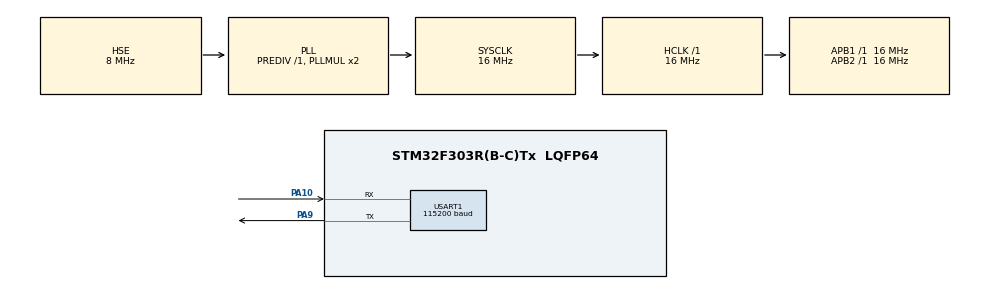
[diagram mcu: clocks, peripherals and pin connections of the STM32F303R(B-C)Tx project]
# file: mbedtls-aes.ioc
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Mcu.Family=STM32F3
Mcu.Name=STM32F303R(B-C)Tx
Mcu.Package=LQFP64
NVIC.PriorityGroup=NVIC_PRIORITYGROUP_4
PA10.Mode=Asynchronous
PA10.Signal=USART1_RX
PA9.Mode=Asynchronous
PA9.Signal=USART1_TX
PF0-OSC_IN.Mode=HSE-External-Oscillator
PF0-OSC_IN.Signal=RCC_OSC_IN
PF1-OSC_OUT.Mode=HSE-External-Oscillator
PF1-OSC_OUT.Signal=RCC_OSC_OUT
ProjectManager.HeapSize=0x200
ProjectManager.StackSize=0x1000
ProjectManager.TargetToolchain=STM32CubeIDE
RCC.AHBFreq_Value=16000000
RCC.APB1Freq_Value=16000000
RCC.APB1TimFreq_Value=16000000
RCC.APB2Freq_Value=16000000
RCC.APB2TimFreq_Value=16000000
RCC.CortexFreq_Value=16000000
RCC.HCLKFreq_Value=16000000
RCC.HSE_VALUE=8000000
RCC.HSI_VALUE=8000000
RCC.LSE_VALUE=32768
RCC.PLLSourceVirtual=RCC_PLLSOURCE_HSE
RCC.SYSCLKFreq_VALUE=16000000
RCC.SYSCLKSourceVirtual=RCC_SYSCLKSOURCE_PLLCLK
RCC.USBFreq_Value=16000000
USART1.BaudRate=115200
USART1.VirtualMode-Asynchronous=VM_ASYNC
board=custom

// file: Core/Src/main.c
/* USER CODE BEGIN Header */
/**
  ******************************************************************************
  * @file           : main.c
  * @brief          : Main program body
  ******************************************************************************
  * @attention
  *
  * Copyright (c) 2024 STMicroelectronics.
  * All rights reserved.
  *
  * This software is licensed under terms that can be found in the LICENSE file
  * in the root directory of this software component.
  * If no LICENSE file comes with this software, it is provided AS-IS.
  *
  ******************************************************************************
  */
/* USER CODE END Header */
#include "main.h"
#include "string.h"

/* USER CODE BEGIN Includes */
#include "mbedtls/config.h"
#include "mbedtls/aes.h"
#define MLEN 32

/* USER CODE END Includes */

UART_HandleTypeDef huart1;

void SystemClock_Config(void);
static void MX_GPIO_Init(void);
static void MX_USART1_UART_Init(void);

int main(void)
{

  /* USER CODE BEGIN 1 */
	mbedtls_aes_context ctx;
	uint8_t key[16] = "AAAAAAAAAACCCCDD";
	const uint8_t iv[16] = {0X00, 0X01, 0X02, 0X03, 0X10, 0X11, 0X12, 0X13, 0X20, 0X21, 0X22, 0X23, 0X30, 0X31, 0X32, 0X33};
	uint8_t tmp_iv[16];
	uint8_t plaintext[MLEN];
	uint8_t ciphertext[MLEN];
	uint8_t pt_output[MLEN];
	int ret = 0;
  /* USER CODE END 1 */

  /* MCU Configuration--------------------------------------------------------*/

  /* Reset of all peripherals, Initializes the Flash interface and the Systick. */
  HAL_Init();

  /* Configure the system clock */
  SystemClock_Config();

  /* Initialize all configured peripherals */
  MX_GPIO_Init();
  MX_USART1_UART_Init();

  /* Infinite loop */
  /* USER CODE BEGIN WHILE */
  while (1)
  {
	  ret = HAL_UART_Receive(&huart1, plaintext, MLEN, HAL_MAX_DELAY);
	  if(ret==HAL_OK)
	  {
	  	  //set the encryption key
	  	  mbedtls_aes_setkey_enc(&ctx, key, 128);
		  __disable_irq();  // disable interrupts
	  	  HAL_GPIO_WritePin(GPIOA, GPIO_PIN_6, 1); // drive the level high before the operation as a trigger signal
	  	  //encrypt
	  	  memcpy(tmp_iv, iv, 16);
	  	  mbedtls_aes_crypt_cbc(&ctx, MBEDTLS_AES_ENCRYPT, MLEN, tmp_iv, plaintext, ciphertext);
	  	  HAL_GPIO_WritePin(GPIOA, GPIO_PIN_6, 0); // drive the level low after the operation
	  	  __enable_irq();  // enable interrupts
	  	  HAL_UART_Transmit(&huart1, ciphertext, MLEN, HAL_MAX_DELAY);

	   	  //set the decryption key
	   	  mbedtls_aes_setkey_dec(&ctx, key, 128);
	  	  __disable_irq();  // disable interrupts
	   	  HAL_GPIO_WritePin(GPIOA, GPIO_PIN_6, 1); // drive the level high before the operation as a trigger signal
 	  	  //decrypt
	   	  memcpy(tmp_iv, iv, 16);
	   	  mbedtls_aes_crypt_cbc(&ctx, MBEDTLS_AES_DECRYPT, MLEN, tmp_iv, ciphertext, pt_output);
	   	  HAL_GPIO_WritePin(GPIOA, GPIO_PIN_6, 0); // drive the level low after the operation
	   	  __enable_irq();  // enable interrupts
	   	  HAL_UART_Transmit(&huart1, pt_output, MLEN, HAL_MAX_DELAY);
	  }
    /* USER CODE END WHILE */

  }
}

void SystemClock_Config(void)
{
  RCC_OscInitTypeDef RCC_OscInitStruct = {0};
  RCC_ClkInitTypeDef RCC_ClkInitStruct = {0};
  RCC_PeriphCLKInitTypeDef PeriphClkInit = {0};

  /** Initializes the RCC Oscillators according to the specified parameters
  * in the RCC_OscInitTypeDef structure.
  */
  RCC_OscInitStruct.OscillatorType = RCC_OSCILLATORTYPE_HSE;
  RCC_OscInitStruct.HSEState = RCC_HSE_ON;
  RCC_OscInitStruct.HSEPredivValue = RCC_HSE_PREDIV_DIV1;
  RCC_OscInitStruct.HSIState = RCC_HSI_ON;
  RCC_OscInitStruct.PLL.PLLState = RCC_PLL_ON;
  RCC_OscInitStruct.PLL.PLLSource = RCC_PLLSOURCE_HSE;
  RCC_OscInitStruct.PLL.PLLMUL = RCC_PLL_MUL2;
  if (HAL_RCC_OscConfig(&RCC_OscInitStruct) != HAL_OK)
  {
    Error_Handler();
  }

  /** Initializes the CPU, AHB and APB buses clocks
  */
  RCC_ClkInitStruct.ClockType = RCC_CLOCKTYPE_HCLK|RCC_CLOCKTYPE_SYSCLK
                              |RCC_CLOCKTYPE_PCLK1|RCC_CLOCKTYPE_PCLK2;
  RCC_ClkInitStruct.SYSCLKSource = RCC_SYSCLKSOURCE_PLLCLK;
  RCC_ClkInitStruct.AHBCLKDivider = RCC_SYSCLK_DIV1;
  RCC_ClkInitStruct.APB1CLKDivider = RCC_HCLK_DIV1;
  RCC_ClkInitStruct.APB2CLKDivider = RCC_HCLK_DIV1;

  if (HAL_RCC_ClockConfig(&RCC_ClkInitStruct, FLASH_LATENCY_0) != HAL_OK)
  {
    Error_Handler();
  }
  PeriphClkInit.PeriphClockSelection = RCC_PERIPHCLK_USART1;
  PeriphClkInit.Usart1ClockSelection = RCC_USART1CLKSOURCE_PCLK2;
  if (HAL_RCCEx_PeriphCLKConfig(&PeriphClkInit) != HAL_OK)
  {
    Error_Handler();
  }
}

static void MX_USART1_UART_Init(void)
{

  huart1.Instance = USART1;
  huart1.Init.BaudRate = 115200;
  huart1.Init.WordLength = UART_WORDLENGTH_8B;
  huart1.Init.StopBits = UART_STOPBITS_1;
  huart1.Init.Parity = UART_PARITY_NONE;
  huart1.Init.Mode = UART_MODE_TX_RX;
  huart1.Init.HwFlowCtl = UART_HWCONTROL_NONE;
  huart1.Init.OverSampling = UART_OVERSAMPLING_16;
  huart1.Init.OneBitSampling = UART_ONE_BIT_SAMPLE_DISABLE;
  huart1.AdvancedInit.AdvFeatureInit = UART_ADVFEATURE_NO_INIT;
  if (HAL_UART_Init(&huart1) != HAL_OK)
  {
    Error_Handler();
  }

}

static void MX_GPIO_Init(void)
{

  /* GPIO Ports Clock Enable */
  __HAL_RCC_GPIOF_CLK_ENABLE();
  __HAL_RCC_GPIOA_CLK_ENABLE();

}

void Error_Handler(void)
{
  __disable_irq();
  while (1)
  {
  }
}
